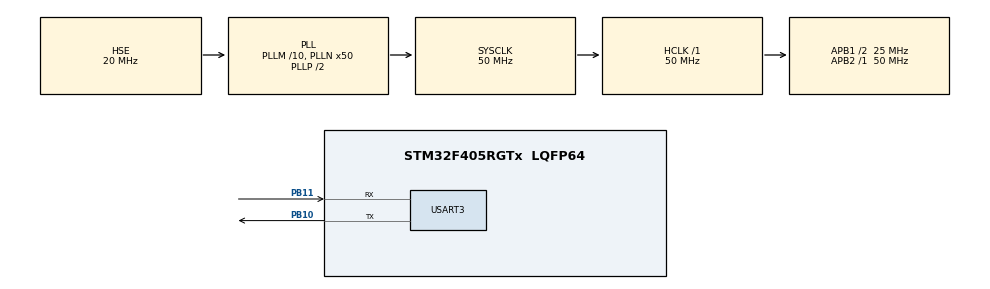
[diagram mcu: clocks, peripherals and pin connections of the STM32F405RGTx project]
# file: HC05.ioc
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Mcu.Family=STM32F4
Mcu.Name=STM32F405RGTx
Mcu.Package=LQFP64
NVIC.PriorityGroup=NVIC_PRIORITYGROUP_4
NVIC.USART3_IRQn=true\:0\:0\:false\:false\:true\:true\:true\:true
PA13.Mode=Serial_Wire
PA13.Signal=SYS_JTMS-SWDIO
PA14.Mode=Serial_Wire
PA14.Signal=SYS_JTCK-SWCLK
PB10.Mode=Asynchronous
PB10.Signal=USART3_TX
PB11.Mode=Asynchronous
PB11.Signal=USART3_RX
PH0-OSC_IN.Mode=HSE-External-Oscillator
PH0-OSC_IN.Signal=RCC_OSC_IN
PH1-OSC_OUT.Mode=HSE-External-Oscillator
PH1-OSC_OUT.Signal=RCC_OSC_OUT
ProjectManager.HeapSize=0x200
ProjectManager.StackSize=0x400
ProjectManager.TargetToolchain=STM32CubeIDE
RCC.48MHZClocksFreq_Value=25000000
RCC.AHBFreq_Value=50000000
RCC.APB1CLKDivider=RCC_HCLK_DIV2
RCC.APB1Freq_Value=25000000
RCC.APB1TimFreq_Value=50000000
RCC.APB2Freq_Value=50000000
RCC.APB2TimFreq_Value=50000000
RCC.CortexFreq_Value=50000000
RCC.HCLKFreq_Value=50000000
RCC.HSE_VALUE=20000000
RCC.HSI_VALUE=16000000
RCC.LSE_VALUE=32768
RCC.PLLM=10
RCC.PLLN=50
RCC.PLLSourceVirtual=RCC_PLLSOURCE_HSE
RCC.SYSCLKFreq_VALUE=50000000
RCC.SYSCLKSource=RCC_SYSCLKSOURCE_PLLCLK
RCC.VCOOutputFreq_Value=100000000
USART3.VirtualMode=VM_ASYNC
board=custom

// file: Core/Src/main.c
/* USER CODE BEGIN Header */
/**
  ******************************************************************************
  * @file           : main.c
  * @brief          : Main program body
  ******************************************************************************
  * @attention
  *
  * Copyright (c) 2025 STMicroelectronics.
  * All rights reserved.
  *
  * This software is licensed under terms that can be found in the LICENSE file
  * in the root directory of this software component.
  * If no LICENSE file comes with this software, it is provided AS-IS.
  *
  ******************************************************************************
  */
/* USER CODE END Header */
#include "main.h"

/* USER CODE BEGIN Includes */
#include <string.h> // Required for strlen()
/* USER CODE END Includes */

/* USER CODE BEGIN PD */
// Define the message strings
#define WELCOME_MESSAGE "STM32 HC-05 Connected. Welcome to MATLAB GUI Test!\r\n"
#define STATUS_MESSAGE "Still running...\r\n"
#define SEND_INTERVAL 2000 // Send status message every 2000 ms (2 seconds)
/* USER CODE END PD */

// UART handler structure (already defined)
UART_HandleTypeDef huart3;

void SystemClock_Config(void);
static void MX_GPIO_Init(void);
static void MX_USART3_UART_Init(void);
// Add a prototype for the Error Handler to satisfy the compiler
void Error_Handler(void);

int main(void)
{

  /* MCU Configuration--------------------------------------------------------*/

  /* Reset of all peripherals, Initializes the Flash interface and the Systick. */
  HAL_Init();

  /* Configure the system clock */
  SystemClock_Config();

  /* Initialize all configured peripherals */
  MX_GPIO_Init();
  MX_USART3_UART_Init();
  /* USER CODE BEGIN 2 */

  // Send initial welcome message
  // Use a short timeout (e.g., 100 ms) since this is non-critical
  HAL_UART_Transmit(&huart3, (uint8_t*)WELCOME_MESSAGE, strlen(WELCOME_MESSAGE), 100);

  // Variable to track the last time a message was sent
  uint32_t last_send_time = HAL_GetTick();

  /* USER CODE END 2 */

  /* Infinite loop */
  /* USER CODE BEGIN WHILE */
  while (1)
  {
      // Check if the periodic send interval has passed
      if ((HAL_GetTick() - last_send_time) >= SEND_INTERVAL)
      {
          // Send the recurring status message over USART3
          HAL_UART_Transmit(&huart3, (uint8_t*)STATUS_MESSAGE, strlen(STATUS_MESSAGE), 100);

          // Update the last send time
          last_send_time = HAL_GetTick();
      }
    /* USER CODE END WHILE */

  }
}

void SystemClock_Config(void)
{
  RCC_OscInitTypeDef RCC_OscInitStruct = {0};
  RCC_ClkInitTypeDef RCC_ClkInitStruct = {0};

  /** Configure the main internal regulator output voltage
  */
  __HAL_RCC_PWR_CLK_ENABLE();
  __HAL_PWR_VOLTAGESCALING_CONFIG(PWR_REGULATOR_VOLTAGE_SCALE1);

  /** Initializes the RCC Oscillators according to the specified parameters
  * in the RCC_OscInitTypeDef structure.
  */
  RCC_OscInitStruct.OscillatorType = RCC_OSCILLATORTYPE_HSE;
  RCC_OscInitStruct.HSEState = RCC_HSE_ON;
  RCC_OscInitStruct.PLL.PLLState = RCC_PLL_ON;
  RCC_OscInitStruct.PLL.PLLSource = RCC_PLLSOURCE_HSE;
  RCC_OscInitStruct.PLL.PLLM = 10;
  RCC_OscInitStruct.PLL.PLLN = 50;
  RCC_OscInitStruct.PLL.PLLP = RCC_PLLP_DIV2;
  RCC_OscInitStruct.PLL.PLLQ = 4;
  if (HAL_RCC_OscConfig(&RCC_OscInitStruct) != HAL_OK)
  {
    Error_Handler();
  }

  /** Initializes the CPU, AHB and APB buses clocks
  */
  RCC_ClkInitStruct.ClockType = RCC_CLOCKTYPE_HCLK|RCC_CLOCKTYPE_SYSCLK
                              |RCC_CLOCKTYPE_PCLK1|RCC_CLOCKTYPE_PCLK2;
  RCC_ClkInitStruct.SYSCLKSource = RCC_SYSCLKSOURCE_PLLCLK;
  RCC_ClkInitStruct.AHBCLKDivider = RCC_SYSCLK_DIV1;
  RCC_ClkInitStruct.APB1CLKDivider = RCC_HCLK_DIV2;
  RCC_ClkInitStruct.APB2CLKDivider = RCC_HCLK_DIV1;

  if (HAL_RCC_ClockConfig(&RCC_ClkInitStruct, FLASH_LATENCY_1) != HAL_OK)
  {
    Error_Handler();
  }
}

static void MX_USART3_UART_Init(void)
{

  huart3.Instance = USART3;
  huart3.Init.BaudRate = 115200;
  huart3.Init.WordLength = UART_WORDLENGTH_8B;
  huart3.Init.StopBits = UART_STOPBITS_1;
  huart3.Init.Parity = UART_PARITY_NONE;
  huart3.Init.Mode = UART_MODE_TX_RX;
  huart3.Init.HwFlowCtl = UART_HWCONTROL_NONE;
  huart3.Init.OverSampling = UART_OVERSAMPLING_16;
  if (HAL_UART_Init(&huart3) != HAL_OK)
  {
    Error_Handler();
  }

}

static void MX_GPIO_Init(void)
{
  /* USER CODE BEGIN MX_GPIO_Init_1 */
  // The GPIO Alternate Function (AF) configuration for USART3 pins (e.g., PB10/PB11 or PC10/PC11)
  // must be done here or typically generated by STM32CubeMX, which is not visible here.
  // Assuming CubeMX generation handles the specific AF setting for USART3.
  /* USER CODE END MX_GPIO_Init_1 */

  /* GPIO Ports Clock Enable */
  __HAL_RCC_GPIOH_CLK_ENABLE();
  __HAL_RCC_GPIOB_CLK_ENABLE();
  __HAL_RCC_GPIOA_CLK_ENABLE();

}

void Error_Handler(void)
{
  __disable_irq();
  while (1)
  {
  }
}
